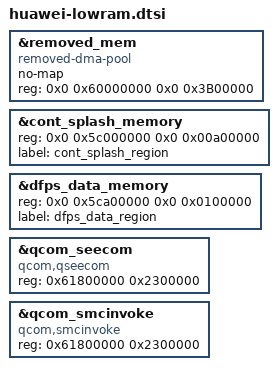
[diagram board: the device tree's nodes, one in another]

&removed_mem {
	compatible = "removed-dma-pool";
	no-map;
	reg = <0x0 0x60000000 0x0 0x3B00000>;
};

&cont_splash_memory {
	reg = <0x0 0x5c000000 0x0 0x00a00000>;
	label = "cont_splash_region";
};

&dfps_data_memory {
	reg = <0x0 0x5ca00000 0x0 0x0100000>;
	label = "dfps_data_region";
};

&qcom_seecom {
	compatible = "qcom,qseecom";
	reg = <0x61800000 0x2300000>;
	reg-names = "secapp-region";
};

&qcom_smcinvoke {
	compatible = "qcom,smcinvoke";
	reg = <0x61800000 0x2300000>;
	reg-names = "secapp-region";
};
